# TC37X register map
File version: 1.0.0
CPU: CM4 r0p1, little endian, MPU, FPU, VTOR, 3 interrupt priority bits
Registers are 16-bit, read-write, reset 0x0 unless marked. A register's access mark holds for its fields unless they carry their own. Offsets are from the block's base; [hi:lo] are bit positions; {n}, {i} and the like mark numbered series; 'fields as' and 'values as' point back to an identical list.

## AMU00 — ce_amu
Base 0xF8508000
Same registers: AMU01 0xF8508100
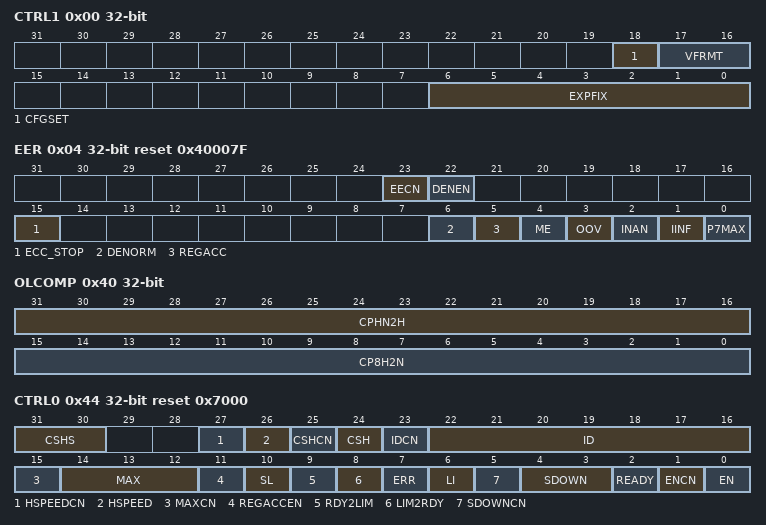
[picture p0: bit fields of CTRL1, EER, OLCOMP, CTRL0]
0x00 CTRL1 32-bit — Control Register 1
  [18] CFGSET — Configuration Set - CFGSET
  [17:16] VFRMT — Parameter Matrix V Format - VFRMT
  [6:0] EXPFIX — Exponent for Fixed Exponent Format - EXPFIX
0x04 EER 32-bit reset 0x40007F — Error Enable Register
  [23] EECN wo — Enable Stop Condition Bit - EECN
  [22] DENEN — Enable Stop on Input Denormalised Number Error. - DENEN
  [15] ECC_STOP ro — Stop on ECC Error - ECC_STOP
  [6] DENORM — Enable Interrupt on Input Denormalised Number Error - DENORM
  [5] REGACC — Enable Interrupt on Register Access during Computation Error - REGACC
  [4] ME — Enable Interrupt on Memory Error - ME
  [3] OOV — Enable Interrupt on Output Overflow - OOV
  [2] INAN — Enable Interrupt on Input NaN Error - INAN
  [1] IINF — Enable Interrupt on Input Infinity Error - IINF
  [0] P7MAX — Enable Interrupt on P7 Over Maximum Error - P7MAX
0x08 P10SINT 32-bit — Parameter p10 Register
  [15:0] NCROSSING — Loop Counter Value to Raise Limit Interrupt - NCROSSING
0x0C P6SINT 32-bit — Parameter p6 Register
  [15:0] NEND — Max Iteration Counter for Outer Loop - NEND
0x10 P7SINT 32-bit — Parameter p7 Register
  [15:0] M — Max Iteration Counter for Inner Loop - M
0x14 P8SINT 32-bit — Parameter p8 Register
  [15:0] NSTART — Start Value for Outer Loop - NSTART
0x18 P9DOUBLELOW32 32-bit — Parameter p9 Register
  [31:0] P9DOUBLE — AMU Parameter p9 Register (Double) - P9DOUBLE
0x1C P9DOUBLEHIGH32 32-bit — Parameter p9 Register
  [31:0] P9DOUBLE — AMU Parameter p9 Register (Double) - P9DOUBLE
0x20 VPFLOAT 32-bit — Coefficient Matrix V Register
  [31:0] VPFLOAT — AMU V Parameter Register (Pointer to Float) - VPFLOAT
0x24 LPFLOAT 32-bit — Coefficient Array L Register
  [31:0] LPFLOAT — AMU Coefficient Array L (Pointer to Float) - LPFLOAT
{0x24+4i} P{i}PFLOAT 32-bit (i=1..3) — Parameter p{i} Register
  [31:0] P{i}PFLOAT — AMU P{i} Parameter Register (Pointer to Float) - P{i}PFLOAT
0x34 P4FLOAT 32-bit — Parameter p4 Register
  [31:0] P4FLOAT — AMU P4 Parameter Register (Float) - P4FLOAT
0x38 P5FLOAT 32-bit — Parameter p5 Register
  [31:0] P5FLOAT — AMU P5 Parameter Register (Float) - P5FLOAT
0x3C UPFLOAT 32-bit — Input Vector u Register
  [31:0] UPFLOAT — AMU Input Vector Register (Pointer to Float) - UPFLOAT
0x40 OLCOMP 32-bit — Parameter p8 Register
  [31:16] CPHN2H — Trigger Value for switch from full to half speed - CPHN2H
  [15:0] CP8H2N — Trigger Value for switch from half to full speed - CP8H2N
0x44 CTRL0 32-bit reset 0x7000 — Control Register 0
  [31:30] CSHS ro — Current Shaping Status - CSHS
  [27] HSPEEDCN wo — Identifier Condition Bit - HSPEEDCN
  [26] HSPEED — Half Speed - HSPEED
  [25] CSHCN wo — Current Shaping Enable Condition Bit - CSHCN
  [24] CSH — Current Shaping Enable - CSH
  [23] IDCN wo — Identifier Condition Bit - IDCN
  [22:16] ID — Identifier - ID
  [15] MAXCN wo — Maximum Speed Condition Bit - MAXCN
  [14:12] MAX — Maximum Speed Control - MAX
  [11] REGACCEN — Allow Register Write when Active - REGACCEN
  [10] SL — Stop on Limit Interrupt - SL
  [9] RDY2LIM — Ready to Limit Interrupt - RDY2LIM
  [8] LIM2RDY — Limit to Ready Interrupt - LIM2RDY
  [7] ERR ro — Error Interrupt - ERR
  [6] LI ro — Limit Interrupt - LI
  [5] SDOWNCN wo — Slowdown Condition Bit - SDOWNCN
  [4:3] SDOWN — Slowdown Flag - SDOWN
  [2] READY ro — Ready Flag - READY
  [1] ENCN wo — Enable Condition Bit - ENCN
  [0] EN — Enable Bit - EN
0x80 ZDOUBLELOW32 32-bit ro reset 0xFFFFFFFF — Return Value Register
  [31:0] ZDOUBLE — AMU Return value z Register (Double) - ZDOUBLE
0x84 ZDOUBLEHIGH32 32-bit ro reset 0x7FFFFFFF — Return Value Register
  [31:0] ZDOUBLE — AMU return value z Register (Double) - ZDOUBLE
0x88 ZFLOAT 32-bit ro reset 0x7FFFFFFF — Return Value Register
  [31:0] ZFLOAT — AMU Result Register (Float) - ZFLOAT
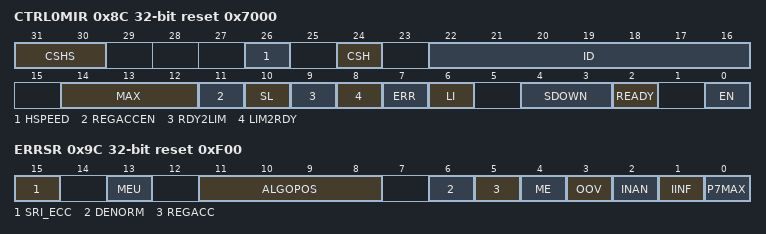
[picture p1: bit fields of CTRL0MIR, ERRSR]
0x8C CTRL0MIR 32-bit ro reset 0x7000 — Control Register 0 Mirror
  [31:30] CSHS — Current Shaping Status - CSHS
  [26] HSPEED — Half Speed - HSPEED
  [24] CSH — Current Shaping Enable - CSH
  [22:16] ID — Identifier - ID
  [14:12] MAX — Maximum Speed Control - MAX
  [11] REGACCEN — Allow Register Write when Active - REGACCEN
  [10] SL — Stop on Limit Interrupt - SL
  [9] RDY2LIM — Ready to Limit Interrupt - RDY2LIM
  [8] LIM2RDY — Limit to Ready Interrupt - LIM2RDY
  [7] ERR — Error Interrupt - ERR
  [6] LI — Limit Interrupt - LI
  [4:3] SDOWN — Slowdown Flag - SDOWN
  [2] READY — Ready Flag - READY
  [0] EN — Enable Bit - EN
0x90 YDOUBLELOW32 32-bit ro reset 0xFFFFFFFF — Intermediate Result yRegister
  [31:0] YDOUBLE — AMU v Result Register (Double) - YDOUBLE
0x94 YDOUBLEHIGH32 32-bit ro reset 0x7FFFFFFF — Intermediate Result yRegister
  [31:0] YDOUBLE — AMU v Result Register (Double) - YDOUBLE
0x98 YFLOAT 32-bit ro reset 0x7FFFFFFF — Intermediate Result y Float Register
  [31:0] YFLOAT — AMU v Result Register (Float) - YFLOAT
0x9C ERRSR 32-bit ro reset 0xF00 — Error Status Register
  [15] SRI_ECC — Uncorrectable Memory Error - SRI_ECC
  [13] MEU — Uncorrectable Memory Error - MEU
  [11:8] ALGOPOS — Algorithm Position - ALGOPOS
  [6] DENORM — Input Denormalised Number Error - DENORM
  [5] REGACC — Register Access during Computation Error - REGACC
  [4] ME — Memory Error - ME
  [3] OOV — Output Overflow - OOV
  [2] INAN — Input NaN Error - INAN
  [1] IINF — Input Infinity Error - IINF
  [0] P7MAX — P7 Over Maximum Error - P7MAX
0xA0 P8SINTMIR 32-bit ro — Interrupt Status Register
  [15:0] NSTART — Start Value for Outer Loop - NSTART
0xA8 UCURRPFLOAT 32-bit ro — Current Input Vector Pointer Register
  fields as UPFLOAT
{0xA8+4i} P{i}CURRPFLOAT 32-bit ro (i=1..3) — Current Parameter p{i} Pointer Register
  [31:0] P{i}PFLOAT — AMU Input Vector Register (Pointer to Float) - P{i}PFLOAT
0xB8 VCURRPFLOAT 32-bit ro — Current Coefficient Matrix V Pointer Register
  [31:0] VPFLOAT — AMU V Coefficient Register (Pointer to Float) - VPFLOAT
0xBC LCURRPFLOAT 32-bit ro — Current Coefficient Matrix L Pointer Register
  [31:0] LPFLOAT — AMU Coefficient Register (Pointer to Float) - LPFLOAT
